# GD32E53x register map
File version: 1.0
CPU: CM33 r0p4, little endian, MPU, FPU, 4 interrupt priority bits
Registers are 32-bit, read-write, reset 0x0 unless marked. A register's access mark holds for its fields unless they carry their own. Offsets are from the block's base; [hi:lo] are bit positions.

## USART0 — Universal synchronous / asynchronous receiver / transmitter
Base 0x40013800
Same registers: USART1 0x40004400
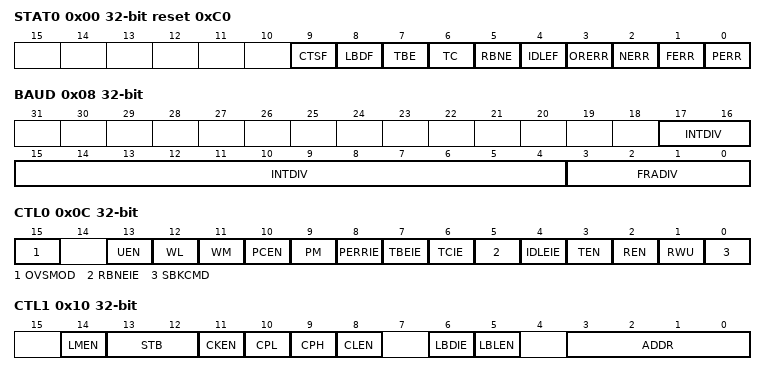
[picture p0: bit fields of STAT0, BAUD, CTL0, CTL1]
0x00 STAT0 access per field reset 0xC0 — Status register 0
  [9] CTSF rw — CTS change flag
  [8] LBDF rw — LIN break detected flag
  [7] TBE ro — Transmit data buffer empty
  [6] TC rw — Transmission complete
  [5] RBNE rw — Read data buffer not empty
  [4] IDLEF ro — IDLE frame detected flag
  [3] ORERR ro — Overrun error
  [2] NERR ro — Noise error flag
  [1] FERR ro — Frame error flag
  [0] PERR ro — Parity error flag
0x04 DATA
  [8:0] DATA — Transmit or read data value
0x08 BAUD — Baud rate register
  [17:4] INTDIV — Integer part of baud-rate divider.
  [3:0] FRADIV — Fraction part of baud-rate divider.
0x0C CTL0 — Control register 0
  [15] OVSMOD — Oversampe mode
  [13] UEN — USART enable
  [12] WL — Word length
  [11] WM — Wakeup method in mute mode
  [10] PCEN — Parity check function enable
  [9] PM — Parity mode
  [8] PERRIE — Parity error interrupt enable.
  [7] TBEIE — Transmitter buffer empty interrupt enable.
  [6] TCIE — Transmission complete interrupt enable.
  [5] RBNEIE — Read data buffer not empty interrupt and overrun error interrupt enable.
  [4] IDLEIE — IDLE line detected interrupt enable.
  [3] TEN — Transmitter enable
  [2] REN — Receiver enable
  [1] RWU — Receiver wakeup from mute mode.
  [0] SBKCMD — Send break command
0x10 CTL1 — Control register 1
  [14] LMEN — LIN mode enable
  [13:12] STB — STOP bits length
  [11] CKEN — CK pin enable
  [10] CPL — CK polarity
  [9] CPH — CK phase
  [8] CLEN — CK Length
  [6] LBDIE — LIN break detected interrupt enable.
  [5] LBLEN — LIN break frame length
  [3:0] ADDR — Address of the USART
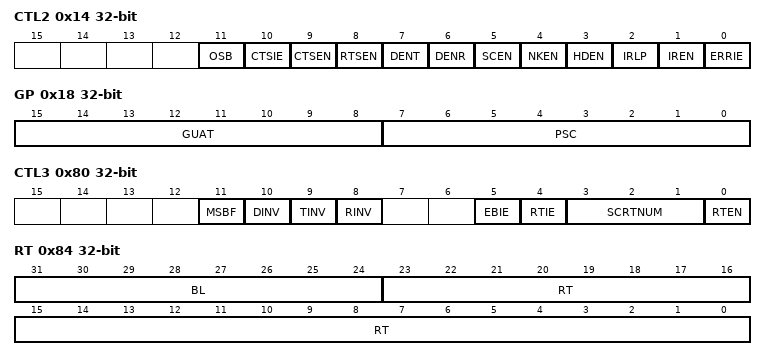
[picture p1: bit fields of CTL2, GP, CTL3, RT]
0x14 CTL2 — Control register 2
  [11] OSB — One sample bit method
  [10] CTSIE — CTS interrupt enable
  [9] CTSEN — CTS enable
  [8] RTSEN — RTS enable
  [7] DENT — DMA request enable for transmission
  [6] DENR — DMA request enable for reception
  [5] SCEN — Smartcard mode enable
  [4] NKEN — NACK enable in Smartcard mode
  [3] HDEN — Half-duplex enable
  [2] IRLP — IrDA low-power
  [1] IREN — IrDA mode enable
  [0] ERRIE — Error interrupt enable
0x18 GP — Guard time and prescaler register
  [15:8] GUAT — Guard time value in smartcard mode
  [7:0] PSC — the division factor that is used to divide the peripheral clock (CK_APB1/CK_APB2) to generate the low-power frequency.
0x80 CTL3 — Control register 3
  [11] MSBF — Most significant bit first
  [10] DINV — Data bit level inversion
  [9] TINV — TX pin level inversion
  [8] RINV — RX pin level inversion
  [5] EBIE — Interrupt enable bit of end of block event
  [4] RTIE — Interrupt enable bit of receive timeout event
  [3:1] SCRTNUM — Smartcard auto-retry number
  [0] RTEN — Receiver timeout enable
0x84 RT — Receiver timeout register
  [31:24] BL — Block Length
  [23:0] RT — Receiver timeout threshold
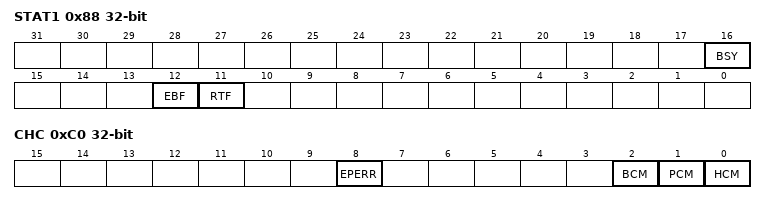
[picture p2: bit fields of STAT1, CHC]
0x88 STAT1 access per field — Status register 1
  [16] BSY ro — Busy flag
  [12] EBF wo — End of block flag
  [11] RTF wo — Receiver timeout flag
0xC0 CHC access per field — Coherence control register
  [8] EPERR wo — Early parity error flag
  [2] BCM rw — Break frame coherence mode
  [1] PCM rw — Parity check coherence mode
  [0] HCM rw — Hardware flow control coherence mode

## USART2 — Universal synchronous / asynchronous receiver / transmitter
Base 0x40004800
Registers as USART0; these are added or differ:
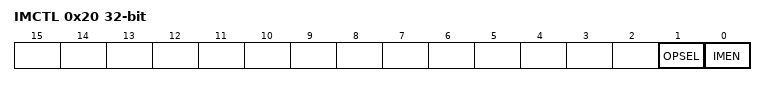
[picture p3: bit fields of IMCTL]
0x20 IMCTL — Infrared modulation control register
  [1] OPSEL — Infrared modulation output polarity selection
  [0] IMEN — Infrared modulation function enable
0x24 IMPW — Infrared modulation pulse width register
  [1:0] WFCFG — Infrared modulation waveform duty cycle configuration
0x28 IMPRE — Infrared modulation prescaler register
  [7:0] CFDIV — Infrared modulation clock frequency division configuration

## UART3 — Universal asynchronous receiver / transmitter
Base 0x40004C00
Same registers: UART4 0x40005000
Registers as USART0, without CTL3, RT, STAT1.
